# CY8C5868AXI_LP035 register map
File version: 0.1
CY8C58LP
Registers are 8-bit, read-write, no defined reset value unless marked. A register's access mark holds for its fields unless they carry their own. Offsets are from the block's base; lines under a group give offsets from that group; [hi:lo] are bit positions; {n}, {i} and the like mark numbered series; 'fields as' and 'values as' point back to an identical list; <NAME> marks a mode.

## Memory map
0x40006422 UART size 0x43

## UART
Base 0x40006422
0x00 RX_UART_RX_ADDRESS1 — RX Address1 Register
0x10 RX_UART_RX_ADDRESS2 — RX Address2 Register
0x20 RX_UART_RX_DATA — RX Data Register
0x22 TX_UART_TX_DATA — TX Data Register
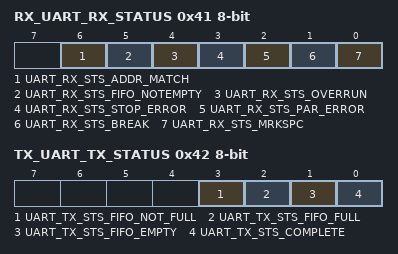
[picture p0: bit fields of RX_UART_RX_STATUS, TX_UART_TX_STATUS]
0x41 RX_UART_RX_STATUS — RX status register
  [6] UART_RX_STS_ADDR_MATCH ro, [5] UART_RX_STS_FIFO_NOTEMPTY ro, [4] UART_RX_STS_OVERRUN ro, [3] UART_RX_STS_STOP_ERROR ro, [2] UART_RX_STS_PAR_ERROR ro, [1] UART_RX_STS_BREAK ro, [0] UART_RX_STS_MRKSPC ro
0x42 TX_UART_TX_STATUS — TX status register
  [3] UART_TX_STS_FIFO_NOT_FULL ro, [2] UART_TX_STS_FIFO_FULL ro, [1] UART_TX_STS_FIFO_EMPTY ro, [0] UART_TX_STS_COMPLETE ro
